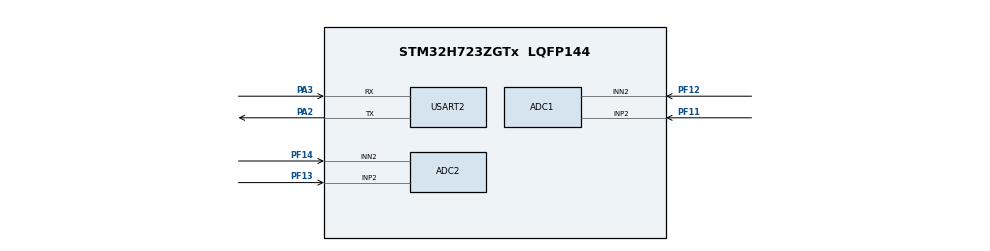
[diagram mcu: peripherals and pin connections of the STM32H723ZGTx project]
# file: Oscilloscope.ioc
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ADC1.Channel-1\#ChannelRegularConversion=ADC_CHANNEL_2
ADC1.ClockPrescaler=ADC_CLOCK_ASYNC_DIV4
ADC1.ContinuousConvMode=DISABLE
ADC1.ConversionDataManagement=ADC_CONVERSIONDATA_DMA_ONESHOT
ADC1.ExternalTrigConv=ADC_EXTERNALTRIG_T3_TRGO
ADC1.NbrOfConversionFlag=1
ADC1.OffsetNumber-1\#ChannelRegularConversion=ADC_OFFSET_NONE
ADC1.OffsetSignedSaturation-1\#ChannelRegularConversion=DISABLE
ADC1.Rank-1\#ChannelRegularConversion=1
ADC1.SamplingTime-1\#ChannelRegularConversion=ADC_SAMPLETIME_1CYCLE_5
ADC1.SingleDiff-1\#ChannelRegularConversion=ADC_DIFFERENTIAL_ENDED
ADC1.master=1
ADC2.Channel-1\#ChannelRegularConversion=ADC_CHANNEL_2
ADC2.ClockPrescaler=ADC_CLOCK_ASYNC_DIV4
ADC2.ContinuousConvMode=DISABLE
ADC2.ConversionDataManagement=ADC_CONVERSIONDATA_DMA_ONESHOT
ADC2.ExternalTrigConv=ADC_EXTERNALTRIG_T4_TRGO
ADC2.NbrOfConversionFlag=1
ADC2.OffsetNumber-1\#ChannelRegularConversion=ADC_OFFSET_NONE
ADC2.OffsetSignedSaturation-1\#ChannelRegularConversion=DISABLE
ADC2.Rank-1\#ChannelRegularConversion=1
ADC2.SamplingTime-1\#ChannelRegularConversion=ADC_SAMPLETIME_1CYCLE_5
ADC2.SingleDiff-1\#ChannelRegularConversion=ADC_DIFFERENTIAL_ENDED
CORTEX_M7.default_mode_Activation=1
Dma.ADC1.0.Direction=DMA_PERIPH_TO_MEMORY
Dma.ADC1.0.EventEnable=DISABLE
Dma.ADC1.0.FIFOMode=DMA_FIFOMODE_DISABLE
Dma.ADC1.0.Instance=DMA1_Stream0
Dma.ADC1.0.MemDataAlignment=DMA_MDATAALIGN_HALFWORD
Dma.ADC1.0.MemInc=DMA_MINC_ENABLE
Dma.ADC1.0.Mode=DMA_NORMAL
Dma.ADC1.0.PeriphDataAlignment=DMA_PDATAALIGN_HALFWORD
Dma.ADC1.0.PeriphInc=DMA_PINC_DISABLE
Dma.ADC1.0.Polarity=HAL_DMAMUX_REQ_GEN_RISING
Dma.ADC1.0.Priority=DMA_PRIORITY_LOW
Dma.ADC1.0.RequestNumber=1
Dma.ADC1.0.SignalID=NONE
Dma.ADC1.0.SyncEnable=DISABLE
Dma.ADC1.0.SyncPolarity=HAL_DMAMUX_SYNC_NO_EVENT
Dma.ADC1.0.SyncRequestNumber=1
Dma.ADC1.0.SyncSignalID=NONE
Dma.ADC2.1.Direction=DMA_PERIPH_TO_MEMORY
Dma.ADC2.1.EventEnable=DISABLE
Dma.ADC2.1.FIFOMode=DMA_FIFOMODE_DISABLE
Dma.ADC2.1.Instance=DMA2_Stream0
Dma.ADC2.1.MemDataAlignment=DMA_MDATAALIGN_HALFWORD
Dma.ADC2.1.MemInc=DMA_MINC_ENABLE
Dma.ADC2.1.Mode=DMA_NORMAL
Dma.ADC2.1.PeriphDataAlignment=DMA_PDATAALIGN_HALFWORD
Dma.ADC2.1.PeriphInc=DMA_PINC_DISABLE
Dma.ADC2.1.Polarity=HAL_DMAMUX_REQ_GEN_RISING
Dma.ADC2.1.Priority=DMA_PRIORITY_LOW
Dma.ADC2.1.RequestNumber=1
Dma.ADC2.1.SignalID=NONE
Dma.ADC2.1.SyncEnable=DISABLE
Dma.ADC2.1.SyncPolarity=HAL_DMAMUX_SYNC_NO_EVENT
Dma.ADC2.1.SyncRequestNumber=1
Dma.ADC2.1.SyncSignalID=NONE
Dma.Request0=ADC1
Dma.Request1=ADC2
Mcu.Family=STM32H7
Mcu.Name=STM32H723ZGTx
Mcu.Package=LQFP144
NVIC.DMA1_Stream0_IRQn=true\:0\:0\:false\:false\:true\:false\:true\:true
NVIC.DMA2_Stream0_IRQn=true\:0\:0\:false\:false\:true\:false\:true\:true
NVIC.PriorityGroup=NVIC_PRIORITYGROUP_4
NVIC.USART2_IRQn=true\:0\:0\:false\:false\:true\:true\:true\:true
PA13(JTMS/SWDIO).Mode=Serial_Wire
PA13(JTMS/SWDIO).Signal=DEBUG_JTMS-SWDIO
PA14(JTCK/SWCLK).Mode=Serial_Wire
PA14(JTCK/SWCLK).Signal=DEBUG_JTCK-SWCLK
PA2.Mode=Asynchronous
PA2.Signal=USART2_TX
PA3.Mode=Asynchronous
PA3.Signal=USART2_RX
PF11.GPIO_Pd=GPIO_NOPULL
PF11.Mode=IN2-Differential
PF11.Signal=ADC1_INP2
PF12.GPIO_Pd=GPIO_NOPULL
PF12.Mode=IN2-Differential
PF12.Signal=ADC1_INN2
PF13.Mode=IN2-Differential
PF13.Signal=ADC2_INP2
PF14.Mode=IN2-Differential
PF14.Signal=ADC2_INN2
PH0-OSC_IN.Mode=HSE-External-Oscillator
PH0-OSC_IN.Signal=RCC_OSC_IN
PH1-OSC_OUT.Mode=HSE-External-Oscillator
PH1-OSC_OUT.Signal=RCC_OSC_OUT
ProjectManager.HeapSize=0x200
ProjectManager.StackSize=0x4000
ProjectManager.TargetToolchain=CMake
RCC.ADCFreq_Value=100000000
RCC.APB1Freq_Value=137500000
RCC.APB2Freq_Value=137500000
RCC.APB3Freq_Value=137500000
RCC.APB4Freq_Value=137500000
RCC.CortexFreq_Value=550000000
RCC.D1PPRE=RCC_APB3_DIV2
RCC.D2PPRE1=RCC_APB1_DIV2
RCC.D2PPRE2=RCC_APB2_DIV2
RCC.D3PPRE=RCC_APB4_DIV2
RCC.DIVM1=2
RCC.DIVM2=2
RCC.DIVN1=44
RCC.DIVN2=16
RCC.DIVN3=128
RCC.DIVP1=1
RCC.EnbaleCSS=true
RCC.HCLKFreq_Value=275000000
RCC.HPRE=RCC_HCLK_DIV2
RCC.PLL2FRACN=0
RCC.PLL3FRACN=0
RCC.PLLFRACN=0
RCC.PLLSourceVirtual=RCC_PLLSOURCE_HSE
RCC.SYSCLKFreq_VALUE=550000000
RCC.SYSCLKSource=RCC_SYSCLKSOURCE_PLLCLK
RCC.USBFreq_Value=275000000
TIM3.Period=1
TIM3.Prescaler=0
TIM3.TIM_MasterOutputTrigger=TIM_TRGO_UPDATE
TIM4.Period=1
TIM4.TIM_MasterOutputTrigger=TIM_TRGO_UPDATE
USART2.VirtualMode-Asynchronous=VM_ASYNC
VP_MEMORYMAP_VS_MEMORYMAP.Mode=CurAppReg
VP_TIM3_VS_ClockSourceINT.Mode=Internal
VP_TIM4_VS_ClockSourceINT.Mode=Internal
board=custom

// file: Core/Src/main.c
/* USER CODE BEGIN Header */
/**
 ******************************************************************************
 * @file           : main.c
 * @brief          : Main program body
 ******************************************************************************
 * @attention
 *
 * Copyright (c) 2025 STMicroelectronics.
 * All rights reserved.
 *
 * This software is licensed under terms that can be found in the LICENSE file
 * in the root directory of this software component.
 * If no LICENSE file comes with this software, it is provided AS-IS.
 *
 ******************************************************************************
 */
/* USER CODE END Header */
#include "main.h"
#include "adc.h"
#include "dma.h"
#include "tim.h"
#include "usart.h"
#include "gpio.h"

/* USER CODE BEGIN Includes */

#include "scope.h"

/* USER CODE END Includes */

void SystemClock_Config(void);
void PeriphCommonClock_Config(void);
static void MPU_Config(void);

int main(void)
{

  /* MPU Configuration--------------------------------------------------------*/
  MPU_Config();

  /* MCU Configuration--------------------------------------------------------*/

  /* Reset of all peripherals, Initializes the Flash interface and the Systick. */
  HAL_Init();

  /* Configure the system clock */
  SystemClock_Config();

  /* Configure the peripherals common clocks */
  PeriphCommonClock_Config();

  /* Initialize all configured peripherals */
  MX_GPIO_Init();
  MX_DMA_Init();
  MX_ADC1_Init();
  MX_ADC2_Init();
  MX_USART2_UART_Init();
  MX_TIM3_Init();
  MX_TIM4_Init();
  /* USER CODE BEGIN 2 */

    scope_init();

  /* USER CODE END 2 */

  /* Infinite loop */
  /* USER CODE BEGIN WHILE */
    while (1)
    {
        scope_update();
    /* USER CODE END WHILE */

    }
}

void SystemClock_Config(void)
{
  RCC_OscInitTypeDef RCC_OscInitStruct = {0};
  RCC_ClkInitTypeDef RCC_ClkInitStruct = {0};

  /** Supply configuration update enable
  */
  HAL_PWREx_ConfigSupply(PWR_LDO_SUPPLY);

  /** Configure the main internal regulator output voltage
  */
  __HAL_PWR_VOLTAGESCALING_CONFIG(PWR_REGULATOR_VOLTAGE_SCALE0);

  while(!__HAL_PWR_GET_FLAG(PWR_FLAG_VOSRDY)) {}

  /** Initializes the RCC Oscillators according to the specified parameters
  * in the RCC_OscInitTypeDef structure.
  */
  RCC_OscInitStruct.OscillatorType = RCC_OSCILLATORTYPE_HSE;
  RCC_OscInitStruct.HSEState = RCC_HSE_ON;
  RCC_OscInitStruct.PLL.PLLState = RCC_PLL_ON;
  RCC_OscInitStruct.PLL.PLLSource = RCC_PLLSOURCE_HSE;
  RCC_OscInitStruct.PLL.PLLM = 2;
  RCC_OscInitStruct.PLL.PLLN = 44;
  RCC_OscInitStruct.PLL.PLLP = 1;
  RCC_OscInitStruct.PLL.PLLQ = 2;
  RCC_OscInitStruct.PLL.PLLR = 2;
  RCC_OscInitStruct.PLL.PLLRGE = RCC_PLL1VCIRANGE_3;
  RCC_OscInitStruct.PLL.PLLVCOSEL = RCC_PLL1VCOWIDE;
  RCC_OscInitStruct.PLL.PLLFRACN = 0;
  if (HAL_RCC_OscConfig(&RCC_OscInitStruct) != HAL_OK)
  {
    Error_Handler();
  }

  /** Initializes the CPU, AHB and APB buses clocks
  */
  RCC_ClkInitStruct.ClockType = RCC_CLOCKTYPE_HCLK|RCC_CLOCKTYPE_SYSCLK
                              |RCC_CLOCKTYPE_PCLK1|RCC_CLOCKTYPE_PCLK2
                              |RCC_CLOCKTYPE_D3PCLK1|RCC_CLOCKTYPE_D1PCLK1;
  RCC_ClkInitStruct.SYSCLKSource = RCC_SYSCLKSOURCE_PLLCLK;
  RCC_ClkInitStruct.SYSCLKDivider = RCC_SYSCLK_DIV1;
  RCC_ClkInitStruct.AHBCLKDivider = RCC_HCLK_DIV2;
  RCC_ClkInitStruct.APB3CLKDivider = RCC_APB3_DIV2;
  RCC_ClkInitStruct.APB1CLKDivider = RCC_APB1_DIV2;
  RCC_ClkInitStruct.APB2CLKDivider = RCC_APB2_DIV2;
  RCC_ClkInitStruct.APB4CLKDivider = RCC_APB4_DIV2;

  if (HAL_RCC_ClockConfig(&RCC_ClkInitStruct, FLASH_LATENCY_3) != HAL_OK)
  {
    Error_Handler();
  }

  /** Enables the Clock Security System
  */
  HAL_RCC_EnableCSS();
}

void PeriphCommonClock_Config(void)
{
  RCC_PeriphCLKInitTypeDef PeriphClkInitStruct = {0};

  /** Initializes the peripherals clock
  */
  PeriphClkInitStruct.PeriphClockSelection = RCC_PERIPHCLK_ADC;
  PeriphClkInitStruct.PLL2.PLL2M = 2;
  PeriphClkInitStruct.PLL2.PLL2N = 16;
  PeriphClkInitStruct.PLL2.PLL2P = 2;
  PeriphClkInitStruct.PLL2.PLL2Q = 2;
  PeriphClkInitStruct.PLL2.PLL2R = 2;
  PeriphClkInitStruct.PLL2.PLL2RGE = RCC_PLL2VCIRANGE_3;
  PeriphClkInitStruct.PLL2.PLL2VCOSEL = RCC_PLL2VCOWIDE;
  PeriphClkInitStruct.PLL2.PLL2FRACN = 0;
  PeriphClkInitStruct.AdcClockSelection = RCC_ADCCLKSOURCE_PLL2;
  if (HAL_RCCEx_PeriphCLKConfig(&PeriphClkInitStruct) != HAL_OK)
  {
    Error_Handler();
  }
}

 /* MPU Configuration */

void MPU_Config(void)
{
  MPU_Region_InitTypeDef MPU_InitStruct = {0};

  /* Disables the MPU */
  HAL_MPU_Disable();

  /** Initializes and configures the Region and the memory to be protected
  */
  MPU_InitStruct.Enable = MPU_REGION_ENABLE;
  MPU_InitStruct.Number = MPU_REGION_NUMBER0;
  MPU_InitStruct.BaseAddress = 0x0;
  MPU_InitStruct.Size = MPU_REGION_SIZE_4GB;
  MPU_InitStruct.SubRegionDisable = 0x87;
  MPU_InitStruct.TypeExtField = MPU_TEX_LEVEL0;
  MPU_InitStruct.AccessPermission = MPU_REGION_NO_ACCESS;
  MPU_InitStruct.DisableExec = MPU_INSTRUCTION_ACCESS_DISABLE;
  MPU_InitStruct.IsShareable = MPU_ACCESS_SHAREABLE;
  MPU_InitStruct.IsCacheable = MPU_ACCESS_NOT_CACHEABLE;
  MPU_InitStruct.IsBufferable = MPU_ACCESS_NOT_BUFFERABLE;

  HAL_MPU_ConfigRegion(&MPU_InitStruct);
  /* Enables the MPU */
  HAL_MPU_Enable(MPU_PRIVILEGED_DEFAULT);

}

void Error_Handler(void)
{
  /* USER CODE BEGIN Error_Handler_Debug */
    /* User can add his own implementation to report the HAL error return state
     */
    __disable_irq();
    while (1)
    {
    }
  /* USER CODE END Error_Handler_Debug */
}
#ifdef USE_FULL_ASSERT
/**
  * @brief  Reports the name of the source file and the source line number
  *         where the assert_param error has occurred.
  * @param  file: pointer to the source file name
  * @param  line: assert_param error line source number
  * @retval None
  */
void assert_failed(uint8_t *file, uint32_t line)
{
  /* USER CODE BEGIN 6 */
    /* User can add his own implementation to report the file name and line
       number, ex: printf("Wrong parameters value: file %s on line %d\r\n",
       file, line) */
  /* USER CODE END 6 */
}
#endif /* USE_FULL_ASSERT */
